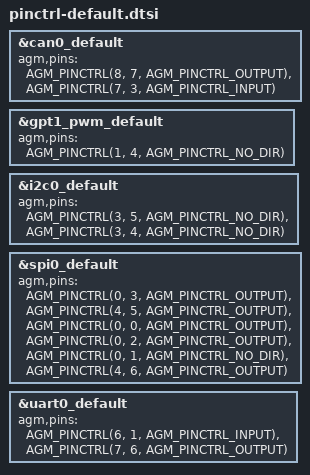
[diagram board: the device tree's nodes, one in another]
/* SPDX-License-Identifier: Apache-2.0 */
/*
 * AUTO-GENERATED by tools/generate_pinctrl_dtsi.py -- DO NOT EDIT.
 * Re-run it after changing the pin list or the AF table.
 *
 * Source dts : ../../../tmp/b_af/zephyr/zephyr.dts
 * AF table   : tools/agm_af_pins.yaml
 * Pin list   : dts/riscv/agm/agrv2k-pins.dtsi (the shared board default)
 */

#include <zephyr/dt-bindings/pinctrl/agm-agrv2k-pinctrl.h>

&can0_default {
	agm,pins =
		<AGM_PINCTRL(8, 7, AGM_PINCTRL_OUTPUT)>,
		<AGM_PINCTRL(7, 3, AGM_PINCTRL_INPUT)>;
};

&gpt1_pwm_default {
	agm,pins =
		<AGM_PINCTRL(1, 4, AGM_PINCTRL_NO_DIR)>;
};

&i2c0_default {
	agm,pins =
		<AGM_PINCTRL(3, 5, AGM_PINCTRL_NO_DIR)>,
		<AGM_PINCTRL(3, 4, AGM_PINCTRL_NO_DIR)>;
};

&spi0_default {
	agm,pins =
		<AGM_PINCTRL(0, 3, AGM_PINCTRL_OUTPUT)>,
		<AGM_PINCTRL(4, 5, AGM_PINCTRL_OUTPUT)>,
		<AGM_PINCTRL(0, 0, AGM_PINCTRL_OUTPUT)>,
		<AGM_PINCTRL(0, 2, AGM_PINCTRL_OUTPUT)>,
		<AGM_PINCTRL(0, 1, AGM_PINCTRL_NO_DIR)>,
		<AGM_PINCTRL(4, 6, AGM_PINCTRL_OUTPUT)>;
};

&uart0_default {
	agm,pins =
		<AGM_PINCTRL(6, 1, AGM_PINCTRL_INPUT)>,
		<AGM_PINCTRL(7, 6, AGM_PINCTRL_OUTPUT)>;
};
